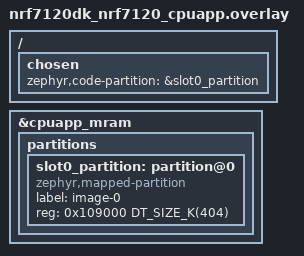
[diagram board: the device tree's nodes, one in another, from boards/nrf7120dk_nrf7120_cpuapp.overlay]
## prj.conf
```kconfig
#
# Copyright (c) 2022 Nordic Semiconductor ASA
#
# SPDX-License-Identifier: LicenseRef-Nordic-5-Clause
#

# Log level
# For more verbose and detailed log output, set the log level to
# CONFIG_WIFI_NRF_CLOUD_LOG_LEVEL_DBG=y instead.
CONFIG_WIFI_NRF_CLOUD_LOG_LEVEL_INF=y

# General config
CONFIG_EVENTS=y
CONFIG_PICOLIBC_IO_FLOAT=y
CONFIG_RESET_ON_FATAL_ERROR=y
CONFIG_NCS_SAMPLES_DEFAULTS=y
CONFIG_DK_LIBRARY=y

# Improved Logging
# CONFIG_LOG_MODE_DEFERRED allows logging from multiple threads simultaneously without creating
# splintered log entries, at the cost of needing a buffer for storing logs.
CONFIG_LOG_MODE_DEFERRED=y

# CONFIG_LOG_BUFFER_SIZE is the aforementioned buffer. A size of 4096 bytes is useful for debugging
# and prototyping, but is probably more than necessary for production-ready firmware.
CONFIG_LOG_BUFFER_SIZE=4096

# Heap and stacks
# Extended memory heap size needed for Wi-Fi operation and encoding JSON-based nRF Cloud Device Messages.
# Add 256 bytes for each additional scanning result (CONFIG_NRF_WIFI_SCAN_MAX_BSS_CNT),
# assuming sane SSID lengths.
CONFIG_HEAP_MEM_POOL_SIZE=40144
CONFIG_HEAP_MEM_POOL_IGNORE_MIN=y
CONFIG_SYSTEM_WORKQUEUE_STACK_SIZE=4096
CONFIG_MAIN_STACK_SIZE=2048

# Enable Networking and Connection Manager.
CONFIG_NETWORKING=y
CONFIG_NET_SOCKETS=y
CONFIG_NET_SOCKETS_OFFLOAD=n
CONFIG_NET_MGMT_EVENT_QUEUE_SIZE=30
CONFIG_NET_CONNECTION_MANAGER_MONITOR_STACK_SIZE=6144
CONFIG_NET_CONNECTION_MANAGER=y

CONFIG_NET_IPV4=y
CONFIG_NET_IPV6=n
#CONFIG_NET_IPV6_NBR_CACHE=n
#CONFIG_NET_IPV6_MLD=n

# DNS
CONFIG_DNS_RESOLVER=y
CONFIG_NET_SOCKETS_DNS_TIMEOUT=30000

# Wi-Fi drivers
CONFIG_WIFI=y


# Wi-Fi conn_mgr bindings
CONFIG_L2_WIFI_CONNECTIVITY=y

# Wi-Fi credentials (simplified Wi-Fi connection setup)
CONFIG_WIFI_CREDENTIALS=y

# Wi-Fi networking and native networking stack
# Note: WIFI_NM_WPA_SUPPLICANT requires 24kB of unused RAM in the final build.
# Memory allocations are fine-tuned with that fact in mind.
CONFIG_WIFI_NM_WPA_SUPPLICANT=y
CONFIG_NET_L2_ETHERNET=y
CONFIG_NET_NATIVE=y
CONFIG_NET_SOCKETS_SOCKOPT_TLS=y
# Allow the FOTA download (HTTPS) to run concurrently with the nRF Cloud CoAP/DTLS conn.
CONFIG_NET_SOCKETS_TLS_MAX_CONTEXTS=2
CONFIG_NET_SOCKETS_TLS_MAX_SESSION_CONTEXTS=2
CONFIG_NET_MAX_CONN=8
CONFIG_NET_MAX_CONTEXTS=8

# Shrink TLS record size and negotiate the smaller size, allowing for
# two concurrent TLS/DTLS sessions (nRF Cloud CoAP + FOTA HTTPS) to fit within the
# available mbedTLS heap (CONFIG_MBEDTLS_HEAP_SIZE).
CONFIG_MBEDTLS_SSL_IN_CONTENT_LEN=4096
CONFIG_MBEDTLS_SSL_OUT_CONTENT_LEN=4096
CONFIG_MBEDTLS_SSL_MAX_FRAGMENT_LENGTH=y

CONFIG_NET_CONTEXT_SNDTIMEO=y
CONFIG_NET_TCP=y
CONFIG_NET_DHCPV4=y

# MBEDTLS base configuration for Wi-Fi TLS/DTLS
CONFIG_MBEDTLS=y
CONFIG_MBEDTLS_ENABLE_HEAP=y
CONFIG_MBEDTLS_SSL_SERVER_NAME_INDICATION=y
CONFIG_MBEDTLS_HEAP_SIZE=65536
# PEM parsing is required for TLS credentials provisioned via the shell
CONFIG_MBEDTLS_PEM_PARSE_C=y
# Needed to parse/verify RSA-signed CA certificates (e.g. Amazon Root CA1, used by
# CONFIG_NRF_CLOUD_PROVISION_CERTIFICATES's hardcoded credentials flow).
CONFIG_MBEDTLS_CIPHERSUITE_TLS_ECDHE_RSA_WITH_AES_128_CBC_SHA256=y
CONFIG_PSA_WANT_ALG_ECDSA=y
# PBKDF2-HMAC is needed for WPA2-PSK passphrase hashing (pbkdf2_sha1)
CONFIG_PSA_WANT_ALG_PBKDF2_HMAC=y
CONFIG_PSA_WANT_ALG_PBKDF2_AES_CMAC_PRF_128=y

# Wait for credential installation to be complete before connecting to nRF Cloud
CONFIG_NRF_CLOUD_CHECK_CREDENTIALS=y

# nRF Cloud
# Transport (MQTT or CoAP) is selected explicitly via mqtt.conf or coap.conf.
CONFIG_NRF_CLOUD=y

# Use compile-time client ID for nRF Cloud
CONFIG_NRF_CLOUD_CLIENT_ID_SRC_HW_ID=y
CONFIG_HW_ID_LIBRARY=y
CONFIG_HW_ID_LIBRARY_SOURCE_DEVICE_ID=y

# Location Services configuration
CONFIG_LOCATION=y
CONFIG_NRF_CLOUD_LOCATION=y
CONFIG_LOCATION_METHOD_WIFI=y
# Keep CONFIG_NRF_WIFI_SCAN_MAX_BSS_CNT and CONFIG_LOCATION_METHOD_WIFI_SCANNING_RESULTS_MAX_CNT
# set to the same value.
CONFIG_NRF_WIFI_SCAN_MAX_BSS_CNT=10
CONFIG_LOCATION_METHOD_WIFI_SCANNING_RESULTS_MAX_CNT=10

# Date Time lib - Used by main application
CONFIG_DATE_TIME=y
# Enable date_time retries for Wi-Fi
# This prevents occasional DNS lookup flukes from
# rendering the device unable to connect until the next
# CONFIG_DATE_TIME_UPDATE_INTERVAL_SECONDS elapses (default 4 hours)
CONFIG_DATE_TIME_RETRY_COUNT=5
# Use a really short retry interval for demo purposes
# 60 seconds to 15 minutes is probably more appropriate for real-world applications
CONFIG_DATE_TIME_RETRY_INTERVAL_SECONDS=20

# Settings - NVS is used (required by WIFI_CREDENTIALS)
CONFIG_SETTINGS=y
CONFIG_SETTINGS_NVS=y
CONFIG_NVS=y

# Flash
CONFIG_FLASH=y
CONFIG_FLASH_PAGE_LAYOUT=y
CONFIG_FLASH_MAP=y

# TFM and Trusted Execution (required for Protected Storage credential management)
# Note: even when using Protected Storage, credentials are still retrieved into insecure
# memory when in use.
CONFIG_BUILD_WITH_TFM=y
CONFIG_TRUSTED_EXECUTION_NONSECURE=y
CONFIG_TFM_PARTITION_PROTECTED_STORAGE=y
# The NOT_SET profile enables all features; we reduce some settings below to save flash and RAM.
CONFIG_TFM_PROFILE_TYPE_NOT_SET=y
CONFIG_TFM_CRYPTO_ASYM_SIGN_MODULE_ENABLED=y

# Credential management shells
CONFIG_SHELL=y
CONFIG_NET_L2_WIFI_SHELL=y
CONFIG_WIFI_CREDENTIALS_SHELL=y
CONFIG_TLS_CREDENTIALS_SHELL=y
# "net iface" shows MAC + IP; "net ping" useful for connectivity checks
CONFIG_NET_SHELL=y
CONFIG_DEVMEM_SHELL=n
CONFIG_TLS_CREDENTIALS_BACKEND_PROTECTED_STORAGE=y
# Increased stack size needed for wifi_cred auto_connect command
CONFIG_SHELL_STACK_SIZE=6144
# nRFCloud credentials can exceed 1024 bytes
CONFIG_TLS_CREDENTIALS_SHELL_CRED_BUF_SIZE=3072
# Needed by the TLS credentials shell
CONFIG_BASE64=y

# Miscellaneous resource allocation tweaks needed to support Wi-Fi
CONFIG_MESSAGE_THREAD_STACK_SIZE=4096
CONFIG_CONNECTION_THREAD_STACK_SIZE=6144
CONFIG_DATE_TIME_THREAD_STACK_SIZE=2048
CONFIG_NET_TX_STACK_SIZE=1024
CONFIG_NET_RX_STACK_SIZE=2048
CONFIG_WIFI_NM_WPA_SUPPLICANT_THREAD_STACK_SIZE=6144
CONFIG_L2_WIFI_CONN_WQ_STACK_SIZE=512
CONFIG_LOCATION_WORKQUEUE_STACK_SIZE=2048
CONFIG_ZVFS_POLL_MAX=8

## TF-M: keep IPC mode (default) for the MQTT build. Enable MM-IOVEC to save RAM.
CONFIG_TFM_PSA_FRAMEWORK_HAS_MM_IOVEC=y

## Memory allocation
CONFIG_NRF_WIFI_CTRL_HEAP_SIZE=20000
CONFIG_NRF_WIFI_DATA_HEAP_SIZE=92856

## Thread stack sizes
CONFIG_APPLICATION_THREAD_STACK_SIZE=2048
CONFIG_NET_MGMT_EVENT_STACK_SIZE=8192

# Enable key generation for nRF Cloud credentials on device, and the associated shell command.
CONFIG_NRF_CLOUD_CREDENTIALS_KEYGEN=y
CONFIG_NRF_CLOUD_CREDENTIALS_KEYGEN_SHELL=y

CONFIG_NRF_CLOUD_CONNECTION_POLL_THREAD_STACK_SIZE=8000

CONFIG_NET_SHELL_SHOW_DISABLED_COMMANDS=n
CONFIG_NET_SHELL_CAPTURE_SUPPORTED=n
CONFIG_NET_SHELL_EVENT_MONITOR_SUPPORTED=n
CONFIG_NET_SHELL_FTP_SUPPORTED=n
CONFIG_NET_SHELL_GPTP_SUPPORTED=n
CONFIG_NET_SHELL_HTTP_CLIENT_SUPPORTED=n
CONFIG_NET_SHELL_HTTP_CLIENT_URL_LEN=128
CONFIG_NET_SHELL_HTTP_CLIENT_CERTIFICATE=""
CONFIG_NET_SHELL_HTTP_CLIENT_CERTIFICATE_TAG=1
CONFIG_NET_SHELL_HTTP_SERVER_SUPPORTED=n
CONFIG_NET_SHELL_PKT_ALLOC_SUPPORTED=n
CONFIG_NET_SHELL_PKT_FILTER_SUPPORTED=n
CONFIG_NET_SHELL_PMTU_SUPPORTED=n
CONFIG_NET_SHELL_PPP_SUPPORTED=n
CONFIG_NET_SHELL_POWER_MANAGEMENT_SUPPORTED=n
CONFIG_NET_SHELL_PTP_SUPPORTED=n
CONFIG_NET_SHELL_ROUTE_SUPPORTED=n
CONFIG_NET_SHELL_SOCKETS_SERVICE_SUPPORTED=n
CONFIG_NET_SHELL_STATISTICS_SUPPORTED=n
CONFIG_NET_SHELL_VIRTUAL_SUPPORTED=n
CONFIG_NET_SHELL_VLAN_SUPPORTED=n
CONFIG_NET_SHELL_WEBSOCKET_SUPPORTED=n
CONFIG_NET_SHELL_QBV_SUPPORTED=n
CONFIG_NET_SHELL_WIREGUARD_SUPPORTED=n
CONFIG_NET_SHELL_QUIC_SUPPORTED=n
CONFIG_NET_SHELL_SSH_SUPPORTED=n
CONFIG_NET_SHELL_DYN_CMD_COMPLETION=n
CONFIG_NET_SHELL_IP_TABLE_SUPPORTED=n
```

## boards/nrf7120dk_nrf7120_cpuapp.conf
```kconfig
#
# Copyright (c) 2026 Nordic Semiconductor ASA
#
# SPDX-License-Identifier: LicenseRef-Nordic-5-Clause
#

# Bump stack size for DTLS handshake (consumed more in an S build).
CONFIG_CONNECTION_THREAD_STACK_SIZE=24576

# Disable location tracking on nRF7120 because connected scans
# cause crashes https://nordicsemi.atlassian.net/browse/WZN-10491
CONFIG_LOCATION_TRACKING=n

CONFIG_FLASH_LOAD_OFFSET=0x1a000
```

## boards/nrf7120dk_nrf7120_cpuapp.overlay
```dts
/*
 * Copyright (c) 2026 Nordic Semiconductor ASA
 *
 * SPDX-License-Identifier: LicenseRef-Nordic-5-Clause
 */

/delete-node/ &boot_partition;
/delete-node/ &slot0_partition;

&cpuapp_mram {
	partitions {
		slot0_partition: partition@0 {
			compatible = "zephyr,mapped-partition";
			label = "image-0";
			reg = <0x109000 DT_SIZE_K(404)>;
		};
	};
};

/ {
	chosen {
		zephyr,code-partition = &slot0_partition;
	};
};
```

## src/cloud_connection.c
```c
/* Copyright (c) 2023 Nordic Semiconductor ASA
 *
 * SPDX-License-Identifier: LicenseRef-Nordic-5-Clause
 */

#include <zephyr/kernel.h>
#include <zephyr/net/socket.h>
#include <zephyr/net/conn_mgr_connectivity.h>
#include <zephyr/net/conn_mgr_monitor.h>
#include <zephyr/logging/log.h>
#include <stdio.h>
#include <date_time.h>
#include <net/nrf_cloud.h>
#include <net/nrf_cloud_codec.h>
#if defined(CONFIG_NRF_CLOUD_COAP)
#include <net/nrf_cloud_coap.h>
#endif
#if defined(CONFIG_MEMFAULT_PERIODIC_UPLOAD)
#include <memfault/ports/zephyr/periodic_upload.h>
#endif
#include "cloud_connection.h"
#include "location_tracking.h"
#include "led_control.h"
#include "shadow_config.h"

LOG_MODULE_REGISTER(cloud_connection, CONFIG_WIFI_NRF_CLOUD_LOG_LEVEL);

/* Internal state */

/* Pendable events that threads can wait for. */
#define NETWORK_READY			BIT(0)
#define CLOUD_CONNECTED			BIT(1)
#define CLOUD_READY			BIT(2)
#define CLOUD_DISCONNECTED		BIT(3)
#define DATE_TIME_KNOWN			BIT(4)
#define L4_EVENT_MASK		(NET_EVENT_L4_CONNECTED | NET_EVENT_L4_DISCONNECTED)
static K_EVENT_DEFINE(cloud_events);

/* Atomic status flag tracking whether an initial association is in progress. */
static atomic_t initial_association;
static bool device_deleted;
static int reconnect_seconds = CONFIG_CLOUD_CONNECTION_RETRY_TIMEOUT_SECONDS;

/* Helper functions for pending on pendable events. */
bool await_network_ready(k_timeout_t timeout)
{
	return k_event_wait(&cloud_events, NETWORK_READY, false, timeout) != 0;
}

bool await_cloud_ready(k_timeout_t timeout)
{
	return k_event_wait(&cloud_events, CLOUD_READY, false, timeout) != 0;
}

bool await_cloud_disconnected(k_timeout_t timeout)
{
	return k_event_wait(&cloud_events, CLOUD_DISCONNECTED, false, timeout) != 0;
}

bool await_date_time_known(k_timeout_t timeout)
{
	return k_event_wait(&cloud_events, DATE_TIME_KNOWN, false, timeout) != 0;
}

bool is_device_deleted(void)
{
	return device_deleted;
}

/* Wait for a connection result, and return true if connection was successful within the timeout,
 * otherwise return false.
 */
static bool await_connection_result(k_timeout_t timeout)
{
	/* After a connection attempt, either CLOUD_CONNECTED or CLOUD_DISCONNECTED will be
	 * raised, depending on whether the connection succeeded.
	 */
	uint32_t events = CLOUD_CONNECTED | CLOUD_DISCONNECTED;

	return (k_event_wait(&cloud_events, events, false, timeout) & CLOUD_CONNECTED) != 0;
}

/* Delayable work item for handling cloud readiness timeout.
 * The work item is scheduled at a delay any time connection starts and is cancelled when the
 * connection to nRF Cloud becomes ready to use (signalled by NRF_CLOUD_EVT_READY).
 *
 * If the work item executes, that means the nRF Cloud connection did not become ready for use
 * within the delay, and thus the connection should be reset (and then try again later).
 */
static void ready_timeout_work_fn(struct k_work *work)
{
	ARG_UNUSED(work);
	LOG_INF("nRF Cloud connection did not become ready in time, disconnecting and retrying...");
	disconnect_cloud();
}

static K_WORK_DELAYABLE_DEFINE(ready_timeout_work, ready_timeout_work_fn);

/* Start the readiness timeout if readiness is not already achieved. */
static void start_readiness_timeout(void)
{
	/* It doesn't make sense to start the readiness timeout if we're already ready. */
	if (k_event_test(&cloud_events, CLOUD_READY)) {
		LOG_DBG("Already ready.");
		return;
	}

	LOG_DBG("Starting cloud connection readiness timeout for %d seconds",
		CONFIG_CLOUD_READY_TIMEOUT_SECONDS);

	k_work_reschedule(&ready_timeout_work, K_SECONDS(CONFIG_CLOUD_READY_TIMEOUT_SECONDS));
}

static void clear_readiness_timeout(void)
{
	LOG_DBG("Stopping cloud connection readiness timeout");
	k_work_cancel_delayable(&ready_timeout_work);
}

/**
 * @brief Update internal state in response to achieving connection.
 */
static void cloud_connected(void)
{
	LOG_INF("Connected to nRF Cloud");

	shadow_config_cloud_connected();

	/* Notify that the nRF Cloud connection is established. */
	k_event_post(&cloud_events, CLOUD_CONNECTED);
}

/**
 * @brief Update internal state in response to achieving readiness.
 */
static void cloud_ready(void)
{
	/* Clear the readiness timeout, since we have become ready. */
	clear_readiness_timeout();

	reconnect_seconds = CONFIG_CLOUD_CONNECTION_RETRY_TIMEOUT_SECONDS;

	/* Notify that the nRF Cloud connection is ready for use. */
	k_event_post(&cloud_events, CLOUD_READY);
	LOG_DBG("Setting CLOUD_READY");

#if defined(CONFIG_MEMFAULT_PERIODIC_UPLOAD)
	/* Only let the Memfault SDK's own periodic upload/FOTA-check timer start doing
	 * anything once we know nRF Cloud is actually reachable, instead of racing Wi-Fi/DNS
	 * readiness at boot (see CONFIG_MEMFAULT_PERIODIC_UPLOAD_ENABLED_DEFAULT=n).
	 */
	memfault_zephyr_port_periodic_upload_enable(true);
#endif
}

/* A callback that the application may register in order to handle custom device messages.
 * This is really a convenience callback to help keep this sample clean and modular. You could
 * implement device message handling directly in the cloud_event_handler if desired.
 */
static dev_msg_handler_cb_t general_dev_msg_handler;
void register_general_dev_msg_handler(dev_msg_handler_cb_t handler_cb)
{
	general_dev_msg_handler = handler_cb;
}

/* This function causes the cloud to disconnect, and updates internal state accordingly.
 *
 * It is also triggerd by cloud disconnection, to update internal state.
 *
 * In this latter case, an unnecessary "Disconnecting from nRF Cloud" and
 * "Already disconnected from nRF Cloud" will be printed.
 *
 * This is done to keep the sample simple, though the log messages may be a bit confusing.
 */
void disconnect_cloud(void)
{
	/* Clear the readiness timeout in case it was running. */
	clear_readiness_timeout();

	/* Clear the Ready and Connected events, no longer accurate. */
	k_event_clear(&cloud_events, CLOUD_READY | CLOUD_CONNECTED);
	LOG_DBG("Cleared CLOUD_READY and CLOUD_CONNECTED");

	/* Clear the initial association flag, no longer accurate. */
	atomic_set(&initial_association, false);

	/* Disconnect from nRF Cloud -- Blocking call
	 * Will no-op and return -EACCES if already disconnected.
	 */
	LOG_INF("Disconnecting from nRF Cloud");
	int err;

#if defined(CONFIG_NRF_CLOUD_MQTT)
	err = nrf_cloud_disconnect();
#elif defined(CONFIG_NRF_CLOUD_COAP)
	err = nrf_cloud_coap_disconnect();
#endif
	/* nrf_cloud_disconnect returns -EACCES if we are not currently in a connected state.
	 * nrf_cloud_coap_disconnect returns -ENOTCONN if socket is not open.
	 */
	if ((err == -EACCES) || (err == -ENOTCONN)) {
		LOG_DBG("Already disconnected from nRF Cloud");
	} else if (err) {
		LOG_ERR("Cannot disconnect from nRF Cloud, error: %d. Continuing anyways", err);
	} else {
		LOG_INF("Successfully disconnected from nRF Cloud");
	}

	/* Fire the disconnected event. */
	k_event_post(&cloud_events, CLOUD_DISCONNECTED);
}

static void network_disconnected(void)
{
#if defined(CONFIG_NRF_CLOUD_MQTT)
	disconnect_cloud();
#elif defined(CONFIG_NRF_CLOUD_COAP)
	if (!nrf_cloud_coap_keepopen_is_supported()) {
		disconnect_cloud();
		return;
	}
	/* When using CoAP we keep the socket open during brief network outages.
	 * There is no need to fully disconnect and cause additional network traffic.
	 */
	if (k_event_test(&cloud_events, CLOUD_DISCONNECTED)) {
		return;
	}
	clear_readiness_timeout();
	k_event_clear(&cloud_events, CLOUD_READY | CLOUD_CONNECTED);
	k_event_post(&cloud_events, CLOUD_DISCONNECTED);
	int err = nrf_cloud_coap_pause();

	if ((err < 0) && (err != -EBADF)) {
		/* -EBADF means it was disconnected. */
		LOG_ERR("Error pausing connection: %d", err);
	}
#endif
}

void cloud_transport_error_detected(void)
{
	/* We could do some kind of ping to verify the connection, but for now,
	 * just assume the detector was correct and force a reconnect.
	 */
	LOG_INF("Communication error detected.");
	network_disconnected();
}

/**
 * @brief Attempt to connect to nRF Cloud and update internal state accordingly.
 *
 * Blocks until connection attempt either succeeds or fails.
 *
 * @retval true if successful
 * @retval false if connection failed
 */
static bool connect_cloud(void)
{
	int err;

	LOG_INF("Connecting to nRF Cloud");

	/* Clear the disconnected flag, no longer accurate. */
	k_event_clear(&cloud_events, CLOUD_DISCONNECTED);

#if defined(CONFIG_NRF_CLOUD_MQTT)
	/* Connect to nRF Cloud -- Non-blocking. State updates are handled in callbacks. */
	err = nrf_cloud_connect();
#elif defined(CONFIG_NRF_CLOUD_COAP)
	/* Connect via CoAP -- blocking. */
	err = nrf_cloud_coap_connect(CONFIG_APP_VERSION);

	/* Cloud is immediately ready and connected since nrf_cloud_coap_connect is blocking. */
	if (!err) {
		cloud_connected();
		cloud_ready();
		return true;
	}
#endif

	/* If we were already connected, treat as a successful connection, but do nothing. */
	if (err == NRF_CLOUD_CONNECT_RES_ERR_ALREADY_CONNECTED) {
		LOG_WRN("Already connected to nRF Cloud");
		return true;
	}

	/* If the connection attempt fails immediately, report and exit. */
	if (err != 0) {
		LOG_ERR("Could not connect to nRF Cloud, error: %d", err);
		return false;
	}

	/* Wait for the connection to either complete or fail. */
	if (!await_connection_result(K_FOREVER)) {
		LOG_ERR("Could not connect to nRF Cloud");
		return false;
	}

	/* If connection succeeded and we aren't already ready, start the readiness timeout.
	 * (Readiness check is performed by start_readiness_timeout).
	 */
	start_readiness_timeout();
	return true;
}

/* External event handlers */

/* Handler for L4/connectivity events
 * This allows the cloud module to react to network gain and loss.
 * The conn_mgr subsystem is responsible for seeking / maintaining network connectivity and
 * firing these events.
 */
static struct net_mgmt_event_callback l4_callback;
static void l4_event_handler(struct net_mgmt_event_callback *cb,
			     uint64_t event, struct net_if *iface)
{
	if (event == NET_EVENT_L4_CONNECTED) {
		LOG_INF("Network connectivity gained!");

		/* Set the network ready flag */
		k_event_post(&cloud_events, NETWORK_READY);

		date_time_update_async(NULL);
	} else if (event == NET_EVENT_L4_DISCONNECTED) {
		LOG_INF("Network connectivity lost!");

		/* Clear the network ready flag */
		k_event_clear(&cloud_events, NETWORK_READY);

		/* Network is now disconnected */
		network_disconnected();
	}
}

/* Handler for date_time library events, used to keep track of whether the current time is known */
static void date_time_event_handler(const struct date_time_evt *date_time_evt)
{
	if (date_time_is_valid()) {
		k_event_post(&cloud_events, DATE_TIME_KNOWN);
	} else {
		k_event_clear(&cloud_events, DATE_TIME_KNOWN);
	}
}

#if defined(CONFIG_NRF_CLOUD_MQTT)
/* Handler for nRF Cloud shadow events */
static void handle_shadow_event(struct nrf_cloud_obj_shadow_data *const shadow)
{
	if (!shadow) {
		return;
	}

	int err;

	if ((shadow->type == NRF_CLOUD_OBJ_SHADOW_TYPE_DELTA) && shadow->delta) {
		/* If there is a pending delta event when the device establishes a cloud connection
		 * it is possible that it will be received before the transform shadow data.
		 * Do not process a delta event until the transform shadow data has been received.
		 * This is only a concern for MQTT.
		 */
		if (shadow_transform_received() == false) {
			LOG_DBG("Ignoring delta until transform shadow is received");
			return;
		}

		if (shadow->delta->is_err) {
			LOG_ERR("Shadow delta error received");
			return;
		}

		LOG_INF("Shadow Delta received");
		bool accept = true;

		err = nrf_cloud_shadow_config_delta_process(&shadow->delta->state,
							    shadow_config_process_cfg,
							    shadow_config_add_cfg_data);
		if (err == -EBADF) {
			LOG_INF("Rejecting shadow delta");
			accept = false;
		} else if (err == -ENOMEM) {
			LOG_ERR("Error handling shadow delta");
			return;
		}

		err = nrf_cloud_obj_shadow_delta_response_encode(&shadow->delta->state, accept);
		if (err) {
			LOG_ERR("Failed to encode shadow response: %d", err);
			return;
		}

		err = nrf_cloud_obj_shadow_update(&shadow->delta->state);
		if (err) {
			LOG_ERR("Failed to send shadow response, error: %d", err);
		}
	} else if ((shadow->type == NRF_CLOUD_OBJ_SHADOW_TYPE_TF) && shadow->transform) {
		LOG_DBG("Shadow: Transform result");

		if (shadow->transform->is_err) {
			LOG_ERR("Shadow transform error: code %d, pos %d, msg %s",
				shadow->transform->error.code,
				shadow->transform->error.pos,
				shadow->transform->error.msg);
		} else {
			LOG_INF("Shadow transform result received");
			err = shadow_config_transform_process(&shadow->transform->result.obj);
			if (err) {
				/* Send the config on an error */
				(void)shadow_config_reported_send();
			}
		}
	} else {
		LOG_WRN("Shadow: Unrecognized shadow event");
	}
}

/* Handler for events from nRF Cloud Lib. */
static void cloud_event_handler(const struct nrf_cloud_evt *nrf_cloud_evt)
{
	switch (nrf_cloud_evt->type) {
	case NRF_CLOUD_EVT_TRANSPORT_CONNECTED:
		LOG_DBG("NRF_CLOUD_EVT_TRANSPORT_CONNECTED");

		/* Handle connection success. */
		cloud_connected();
		break;
	case NRF_CLOUD_EVT_TRANSPORT_CONNECTING:
		LOG_DBG("NRF_CLOUD_EVT_TRANSPORT_CONNECTING");
		break;
	case NRF_CLOUD_EVT_TRANSPORT_CONNECT_ERROR:
		LOG_DBG("NRF_CLOUD_EVT_TRANSPORT_CONNECT_ERROR: %d", nrf_cloud_evt->status);

		/* Disconnect from cloud immediately rather than wait for retry timeout. */
		disconnect_cloud();

		break;
	case NRF_CLOUD_EVT_USER_ASSOCIATION_REQUEST:
		LOG_DBG("NRF_CLOUD_EVT_USER_ASSOCIATION_REQUEST");
		/* This event indicates that the user must associate the device with their
		 * nRF Cloud account in the nRF Cloud portal.
		 *
		 * The device must then disconnect and reconnect to nRF Cloud after association
		 * succeeds.
		 */
		LOG_INF("Please add this device to your cloud account in the nRF Cloud portal.");

		/* Store the fact that this is an initial association.
		 *
		 * This will cause the next NRF_CLOUD_EVT_USER_ASSOCIATED event to
		 * disconnect and reconnect the device to nRF Cloud, which is required
		 * when devices are first associated with an nRF Cloud account.
		 */
		atomic_set(&initial_association, true);
		break;
	case NRF_CLOUD_EVT_USER_ASSOCIATED:
		LOG_DBG("NRF_CLOUD_EVT_USER_ASSOCIATED");
		/* Indicates successful association with an nRF Cloud account.
		 * Fired every time the device connects (unless the device is not associated).
		 *
		 * If this is an initial association, the device must disconnect and
		 * and reconnect before using nRF Cloud.
		 */
		device_deleted = false;
		if (atomic_get(&initial_association)) {
			/* Disconnect as is required.
			 * The connection loop will handle reconnection afterwards.
			 */
			LOG_INF("Device successfully associated with cloud! Reconnecting");
			reconnect_seconds = 1;
			disconnect_cloud();
		}
		break;
	case NRF_CLOUD_EVT_READY:
		LOG_DBG("NRF_CLOUD_EVT_READY");

		/* Handle achievement of readiness */
		cloud_ready();

		/* The nRF Cloud library will automatically update the
		 * device's shadow based on the build configuration.
		 * See config NRF_CLOUD_SEND_SHADOW_INFO for details.
		 */
		break;
	case NRF_CLOUD_EVT_SENSOR_DATA_ACK:
		LOG_DBG("NRF_CLOUD_EVT_SENSOR_DATA_ACK");
		break;
	case NRF_CLOUD_EVT_TRANSPORT_DISCONNECTED:
		LOG_DBG("NRF_CLOUD_EVT_TRANSPORT_DISCONNECTED");

		/* The nRF Cloud library itself has disconnected for some reason.
		 * Execute a manual disconnect so that the event flags are updated.
		 * The internal nrf_cloud_disconnect call will no-op.
		 */
		disconnect_cloud();

		break;
	case NRF_CLOUD_EVT_ERROR:
		LOG_DBG("NRF_CLOUD_EVT_ERROR: %d", nrf_cloud_evt->status);
		break;
	case NRF_CLOUD_EVT_RX_DATA_GENERAL:
		LOG_DBG("NRF_CLOUD_EVT_RX_DATA_GENERAL");
		LOG_DBG("%d bytes received from cloud", nrf_cloud_evt->data.len);
		/* Pass the device message along to the application, if it is listening */
		if (general_dev_msg_handler) {
			/* To keep the sample simple, we invoke the callback directly.
			 * If you want to do complex operations in this callback without blocking
			 * receipt of data from nRF Cloud, you should set up a work queue and pass
			 * messages to it either here, or from inside the callback.
			 */
			general_dev_msg_handler(&nrf_cloud_evt->data);
		}

		break;
	case NRF_CLOUD_EVT_RX_DATA_DISCON:
		LOG_DBG("NRF_CLOUD_EVT_RX_DATA_DISCON");
		LOG_INF("Device was removed from your account.");
		device_deleted = true;
		break;
	case NRF_CLOUD_EVT_RX_DATA_SHADOW: {
		LOG_DBG("NRF_CLOUD_EVT_RX_DATA_SHADOW");
		handle_shadow_event(nrf_cloud_evt->shadow);
		break;
	}
	default:
		LOG_DBG("Unknown event type: %d", nrf_cloud_evt->type);
		break;
	}
}
#endif /* CONFIG_NRF_CLOUD_MQTT */

/**
 * @brief Set up for the nRF Cloud connection
 *
 * Sets up required event hooks and initializes the nrf_cloud library.
 *
 * @return int - 0 on success, otherwise negative error code.
 */
static int setup_cloud(void)
{
	int err;

	/* Register to be notified when the device has figured out the current time. */
	date_time_register_handler(date_time_event_handler);

#if defined(CONFIG_NRF_CLOUD_MQTT)
	/* Initialize nrf_cloud library. */
	struct nrf_cloud_init_param params = {
		.event_handler = cloud_event_handler,
		.application_version = CONFIG_APP_VERSION
	};

	err = nrf_cloud_init(&params);
	if (err) {
		LOG_ERR("nRF Cloud library could not be initialized, error: %d", err);
		return err;
	}

#elif defined(CONFIG_NRF_CLOUD_COAP)
	err = nrf_cloud_coap_init();
	if (err) {
		LOG_ERR("Failed to initialize CoAP client: %d", err);
		return err;
	}
#endif /* CONFIG_NRF_CLOUD_COAP */

	return 0;
}

/* Check whether nRF Cloud credentials are installed. If not, sleep forever. */
static void check_credentials(void)
{
	int status = nrf_cloud_credentials_configured_check();

	if (status == -ENOTSUP) {
		LOG_WRN("nRF Cloud credentials are not installed. "
			"Please install and reboot.");
	} else if (status == -ENOPROTOOPT) {
		LOG_WRN("Required root CA certificate is missing.");
	} else {
		if (status) {
			LOG_ERR("Error while checking for credentials: %d. Proceeding anyway.",
				status);
		}
		return;
	}
	/* Save power since credentials will not work. */
	printk("Here I should've down iface but I wont', ha-ha\n");
//	conn_mgr_all_if_down(true);
//	k_sleep(K_FOREVER);
}

void cloud_connection_thread_fn(void)
{
	long_led_pattern(LED_WAITING);

	/* Setup handler for Zephyr NET Connection Manager events. */
	net_mgmt_init_event_callback(&l4_callback, l4_event_handler, L4_EVENT_MASK);
	net_mgmt_add_event_callback(&l4_callback);

	/* Enable the connection manager for all interfaces and allow them to connect. */
	conn_mgr_all_if_up(true);

	LOG_INF("Enabling connectivity...");
	conn_mgr_all_if_connect(true);

	LOG_INF("Setting up nRF Cloud library...");
	if (setup_cloud()) {
		LOG_ERR("Fatal: nRF Cloud library setup failed");
		long_led_pattern(LED_FAILURE);
		return;
	}

	/* Check for credentials, if the feature is enabled. */
	if (IS_ENABLED(CONFIG_NRF_CLOUD_CHECK_CREDENTIALS)) {
		check_credentials();
	}

	/* Indefinitely maintain a connection to nRF Cloud whenever the network is reachable. */
	while (true) {
		LOG_INF("Waiting for network ready...");

		if (IS_ENABLED(CONFIG_LED_VERBOSE_INDICATION)) {
			long_led_pattern(LED_WAITING);
		}
		(void)await_network_ready(K_FOREVER);

		LOG_INF("Network is ready");

		/* Obtain time before connecting to the cloud,
		 * otherwise NTP query will fail.
		 */
		LOG_INF("Waiting to obtain date/time");
		(void)await_date_time_known(K_FOREVER);

		/* Attempt to connect to nRF Cloud. */
		if (connect_cloud()) {
			LOG_DBG("Monitoring nRF Cloud connection");

			/* and then wait patiently for a connection problem. */
			(void)await_cloud_disconnected(K_FOREVER);

			LOG_INF("Disconnected from nRF Cloud");
		}

		LOG_INF("Retrying in %d seconds...", reconnect_seconds);

		/* Wait a bit before trying again. */
		k_sleep(K_SECONDS(reconnect_seconds));
	}
}
```
